# STM32U599 register map
File version: 1.7
CPU: CM33 r0p1, little endian, MPU, FPU, 4 interrupt priority bits
Registers are 32-bit, read-write, reset 0x0 unless marked. A register's access mark holds for its fields unless they carry their own. Offsets are from the block's base; [hi:lo] are bit positions; {n}, {i} and the like mark numbered series.

## GFXMMU
Base 0x4002C000
Same registers: SEC_GFXMMU 0x5002C000
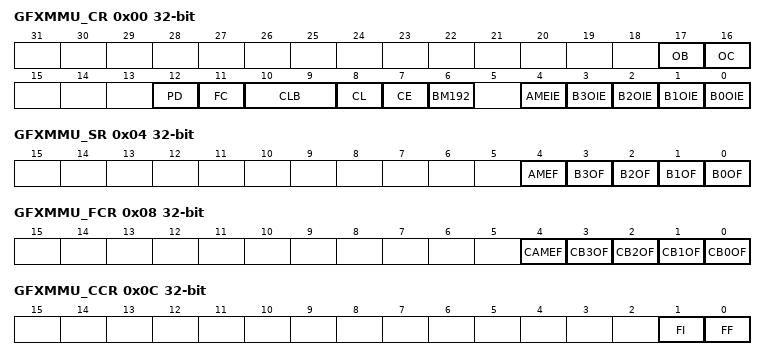
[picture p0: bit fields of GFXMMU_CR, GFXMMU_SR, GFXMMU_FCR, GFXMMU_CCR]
0x00 GFXMMU_CR — GFXMMU configuration register
  [17] OB — Outter bufferability
    0=No bufferable; 1=Bufferable
  [16] OC — Outter cachability
    0=No cachable; 1=Cachable
  [12] PD — Prefetch disable
    0=Prefetch enable; 1=Prefetch disable
  [11] FC — Force caching
    0=Caching not forced; 1=Caching forced
  [10:9] CLB — Cache lock buffer
    {v}=Cache locked on buffer {v} (v=0..3)
  [8] CL — Cache lock
    0=Cache not locked; 1=Cache locked to a buffer
  [7] CE — Cache enable
    0=Cache disable; 1=Cache enable
  [6] BM192 — 192 Block mode
    0=256 blocks per line; 1=192 blocks per line
  [4] AMEIE — AHB master error interrupt enable
    0=Interrupt disable; 1=Interrupt enabled
  [n] B{n}OIE (n=0..3) — Buffer {n} overflow interrupt enable
    0=Interrupt disable; 1=Interrupt enabled
0x04 GFXMMU_SR ro — GFXMMU status register
  [4] AMEF — AHB master error flag
  [n] B{n}OF (n=0..3) — Buffer {n} overflow flag
0x08 GFXMMU_FCR — GFXMMU flag clear register
  [4] CAMEF — Clear AHB master error flag
  [n] CB{n}OF (n=0..3) — Clear buffer {n} overflow flag
0x0C GFXMMU_CCR — GFXMMU cache control register
  [1] FI — Force invalidate
    0=Invalidation process complete; 1=Force invalidation/invalidation process on going
  [0] FF — Force flush
    0=Flushing process complete; 1=Force flush/flushing process on going
0x10 GFXMMU_DVR — GFXMMU default value register
  [31:0] DV — Default value
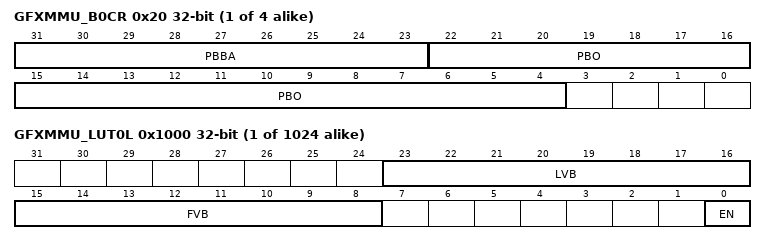
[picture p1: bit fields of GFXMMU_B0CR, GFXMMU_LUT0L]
{0x20+4i} GFXMMU_B{i}CR (i=0..3) — GFXMMU buffer {i} configuration register
  [31:23] PBBA — Physical buffer base address
  [22:4] PBO — Physical buffer offset
{0x1000+8i} GFXMMU_LUT{i}L (i=0..1023) — GFXMMU LUT entry {i} low
  [23:16] LVB — Last Valid Block
  [15:8] FVB — First Valid Block
  [0] EN — Enable
    0=Line is disabled (no MMU evaluation is performed); 1=Line is enabled (MMU evaluation is performed)
{0x1004+8i} GFXMMU_LUT{i}H (i=0..1023) — GFXMMU LUT entry {i} high
  [21:4] LO — Line offset

## GTZC1_MPCBB1
Base 0x40032C00
Same registers: SEC_GTZC1_MPCBB1 0x50032C00
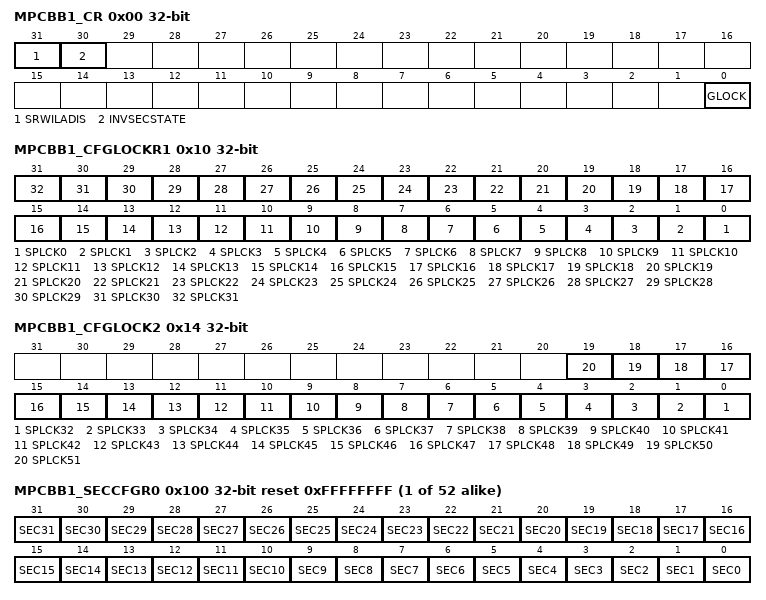
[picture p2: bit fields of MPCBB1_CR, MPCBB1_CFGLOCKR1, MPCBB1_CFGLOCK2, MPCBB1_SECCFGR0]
0x00 MPCBB1_CR — MPCBB control register
  [31] SRWILADIS — secure read/write illegal access disable
  [30] INVSECSTATE — SRAMx clocks security state
  [0] GLOCK — lock the control register of the MPCBB until next reset
0x10 MPCBB1_CFGLOCKR1 — GTZC1 SRAMz MPCBB configuration lock register 1
  [n] SPLCK{n} (n=0..31)
0x14 MPCBB1_CFGLOCK2 — GTZC1 SRAMz MPCBB configuration lock register 2
  [n-32] SPLCK{n} (n=32..51)
{0x100+4i} MPCBB1_SECCFGR{i} reset 0xFFFFFFFF (i=0..51) — MPCBBx security configuration for super-block x register
  [n] SEC{n} (n=0..31)
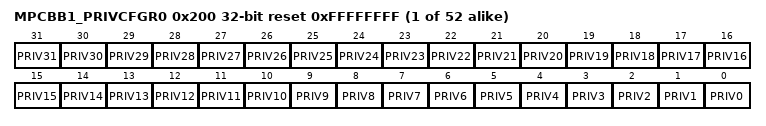
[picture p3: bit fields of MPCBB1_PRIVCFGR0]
{0x200+4i} MPCBB1_PRIVCFGR{i} reset 0xFFFFFFFF (i=0..51) — MPCBB privileged configuration for super-block x register
  [n] PRIV{n} (n=0..31)

## GTZC1_MPCBB2
Base 0x40033000
Same registers: SEC_GTZC1_MPCBB2 0x50033000
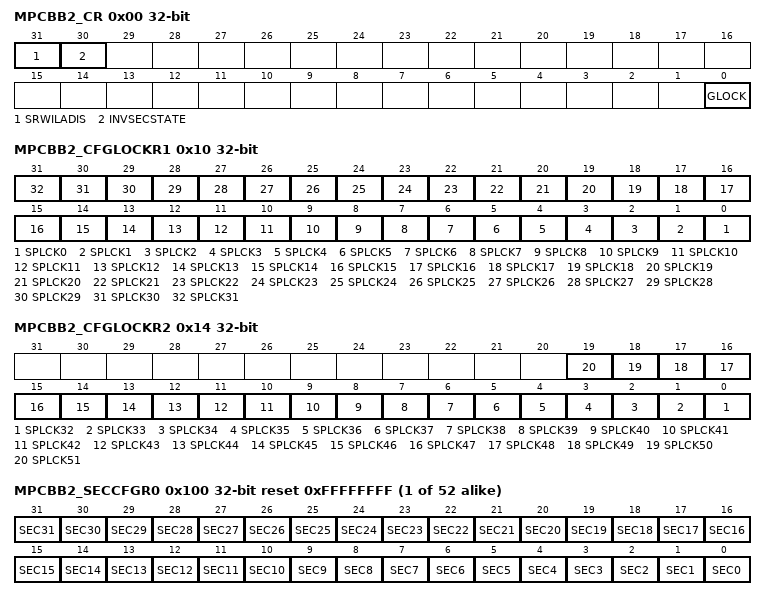
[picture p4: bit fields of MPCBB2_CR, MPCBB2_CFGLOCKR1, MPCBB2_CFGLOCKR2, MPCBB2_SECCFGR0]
0x00 MPCBB2_CR — MPCBB control register
  [31] SRWILADIS — secure read/write illegal access disable
  [30] INVSECSTATE — SRAMx clocks security state
  [0] GLOCK — lock the control register of the MPCBB until next reset
0x10 MPCBB2_CFGLOCKR1 — GTZC1 SRAMz MPCBB configuration lock register
  [n] SPLCK{n} (n=0..31)
0x14 MPCBB2_CFGLOCKR2 — GTZC1 SRAMz MPCBB configuration lock register 2
  [n-32] SPLCK{n} (n=32..51)
{0x100+4i} MPCBB2_SECCFGR{i} reset 0xFFFFFFFF (i=0..51) — MPCBBx security configuration for super-block x register
  [n] SEC{n} (n=0..31)
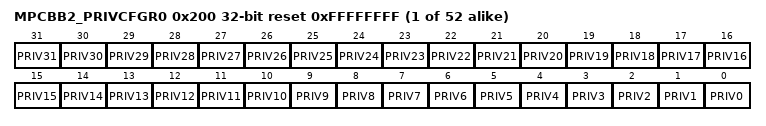
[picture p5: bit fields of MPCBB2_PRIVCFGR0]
{0x200+4i} MPCBB2_PRIVCFGR{i} reset 0xFFFFFFFF (i=0..51) — MPCBB privileged configuration for super-block x register
  [n] PRIV{n} (n=0..31)

## GTZC1_MPCBB3
Base 0x40033400
Same registers: SEC_GTZC1_MPCBB3 0x50033400
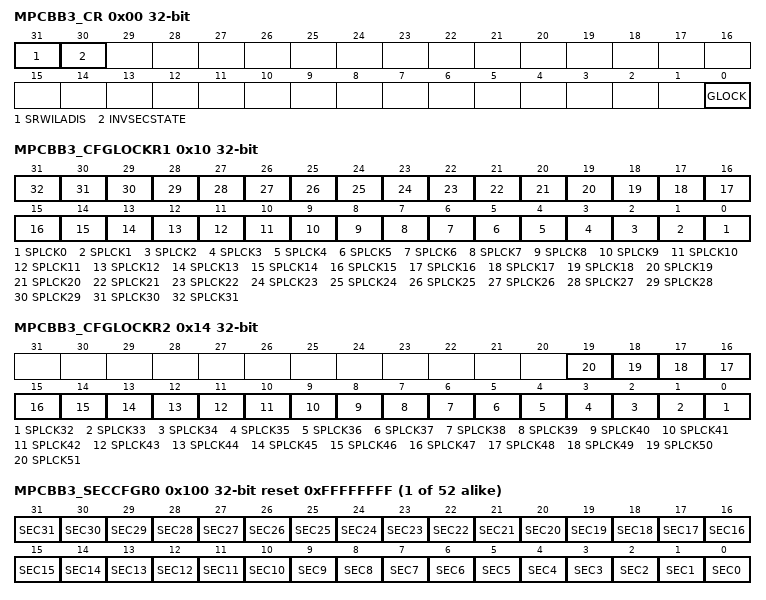
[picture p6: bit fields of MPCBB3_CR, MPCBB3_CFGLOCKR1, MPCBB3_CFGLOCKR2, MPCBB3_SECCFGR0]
0x00 MPCBB3_CR — MPCBB control register
  [31] SRWILADIS — secure read/write illegal access disable
  [30] INVSECSTATE — SRAMx clocks security state
  [0] GLOCK — lock the control register of the MPCBB until next reset
0x10 MPCBB3_CFGLOCKR1 — GTZC1 SRAMz MPCBB configuration lock register
  [n] SPLCK{n} (n=0..31)
0x14 MPCBB3_CFGLOCKR2 — GTZC1 SRAMz MPCBB configuration lock register 2
  [n-32] SPLCK{n} (n=32..51)
{0x100+4i} MPCBB3_SECCFGR{i} reset 0xFFFFFFFF (i=0..51) — MPCBBx security configuration for super-block x register
  [n] SEC{n} (n=0..31)
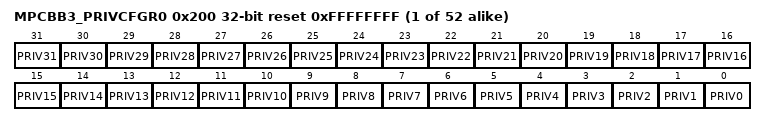
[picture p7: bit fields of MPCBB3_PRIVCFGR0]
{0x200+4i} MPCBB3_PRIVCFGR{i} reset 0xFFFFFFFF (i=0..51) — MPCBB privileged configuration for super-block x register
  [n] PRIV{n} (n=0..31)

## Notices in the file
Copyright (c) 2025 STMicroelectronics.
SPDX-License-Identifier: Apache-2.0
Licensed under the Apache License, Version 2.0 (the "License");
you may not use this file except in compliance with the License.
You may obtain a copy of the License at
http://www.apache.org/licenses/LICENSE-2.0
Unless required by applicable law or agreed to in writing, software
distributed under the License is distributed on an "AS IS" BASIS,
WITHOUT WARRANTIES OR CONDITIONS OF ANY KIND, either express or implied.
See the License for the specific language governing permissions and
limitations under the License.
